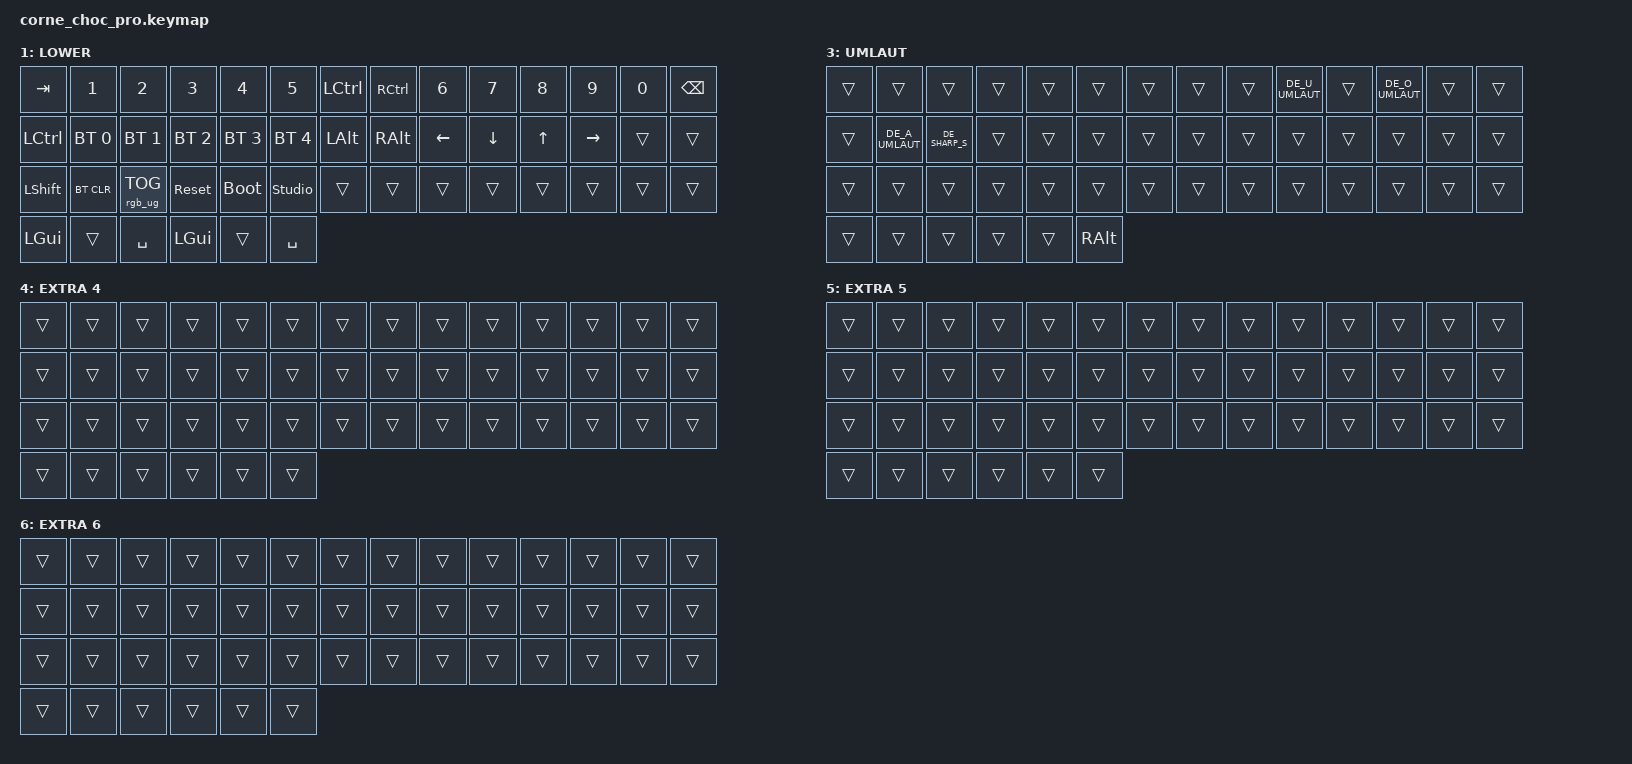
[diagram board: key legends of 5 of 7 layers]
/*
 * Copyright (c) 2020 The ZMK Contributors
 *
 * SPDX-License-Identifier: MIT
 */

#include <behaviors.dtsi>
#include <dt-bindings/zmk/keys.h>
#include <dt-bindings/zmk/bt.h>
#include <dt-bindings/zmk/rgb.h>

/ {
    chosen {
        zmk,physical-layout = &default_layout;
    };
};

/ {
    keymap {
        compatible = "zmk,keymap";

        default_layer {
            display-name = "QWERTY";
            // --------------------------------------------------------------------------------
            // | TAB | Q | W | E | R | T | MUTE | PP | Y | U | I | O | P | BSPC |
            // | CTRL | A | S | D | F | G | LALT | MO3 | H | J | K | L | ; | ' |
            // | SHFT | Z | X | C | V | B | | N | M | , | . | / | ESC |
            // | GUI | LWR | SPC | | ENT | RSE | MO3 |
            bindings = <
                &kp TAB &kp Q &kp W &kp E &kp R &kp T &kp C_MUTE &kp C_PP &kp Y &kp U &kp I &kp O &kp P &kp BSPC
                &kp LCTRL &kp A &kp S &kp D &kp F &kp G &kp LALT  &kp H &kp J &kp K &kp L &kp SEMI &kp SQT
                &kp LSHFT &kp Z &kp X &kp C &kp V &kp B &kp N &kp M &kp COMMA &kp DOT &kp FSLH &kp ESC
                &kp LGUI &mo 1 &kp SPACE &kp RET &mo 2 
            >;
            sensor-bindings = <&inc_dec_kp C_VOL_DN C_VOL_UP &inc_dec_kp PG_UP PG_DN &inc_dec_kp C_PREV C_NEXT &inc_dec_kp C_BRI_DN C_BRI_UP>;
        };

        extra_layer_1 {
            display-name = "LOWER";
            bindings = <
                &kp TAB &kp N1 &kp N2 &kp N3 &kp N4 &kp N5 &kp LCTRL &kp RCTRL &kp N6 &kp N7 &kp N8 &kp N9 &kp N0 &kp BSPC
                &kp LCTRL &bt BT_SEL 0 &bt BT_SEL 1 &bt BT_SEL 2 &bt BT_SEL 3 &bt BT_SEL 4 &kp LALT &kp RALT &kp LEFT &kp DOWN &kp UP &kp RIGHT &trans &trans
                &kp LSHFT &bt BT_CLR &rgb_ug RGB_TOG &sys_reset &bootloader &studio_unlock &trans &trans &trans &trans &trans &trans &trans &trans
                &kp LGUI &trans &kp SPACE &kp LGUI &trans &kp SPACE
            >;
        };

        extra_layer_2 {
            display-name = "RAISE";
            bindings = <
                &kp TAB &kp EXCL &kp AT &kp HASH &kp DLLR &kp PRCNT &kp LCTRL &kp RCTRL &kp CARET &kp AMPS &kp ASTRK &kp LPAR &kp RPAR &kp BSPC
                &kp LCTRL &trans &trans &trans &trans &trans &kp LALT &kp RALT &kp MINUS &kp EQUAL &kp LBKT &kp RBKT &kp BSLH &kp GRAVE
                &kp LSHFT &trans &trans &trans &trans &trans &kp UNDER &kp PLUS &kp LBRC &kp RBRC &kp PIPE &kp TILDE &kp LGUI &trans
                &kp SPACE &kp RET &trans &kp RALT
            >;
        };

        extra_layer_3 {
            display-name = "UMLAUT";
            // Umlaut layer: Hold MO3 (was RALT/AltGr) to activate
            // A->Ä, O->Ö, U->Ü, S->ß, E->€, Z->å (optional)
            // Other keys pass through as transparent
            bindings = <
                &trans &trans &trans &trans &trans &trans &trans &trans &trans &kp DE_U_UMLAUT &trans &kp DE_O_UMLAUT &trans &trans
                &trans &kp DE_A_UMLAUT &kp DE_SHARP_S &trans &trans &trans &trans &trans &trans &trans &trans &trans &trans &trans
                &trans &trans &trans &trans &trans &trans &trans &trans &trans &trans &trans &trans &trans &trans
                &trans &trans &trans &trans &trans &kp RALT
            >;
        };

        extra_layer_4 {
            display-name = "EXTRA 4";
            bindings = <
                &trans &trans &trans &trans &trans &trans &trans &trans &trans &trans &trans &trans &trans &trans
                &trans &trans &trans &trans &trans &trans &trans &trans &trans &trans &trans &trans &trans &trans
                &trans &trans &trans &trans &trans &trans &trans &trans &trans &trans &trans &trans &trans &trans
                &trans &trans &trans &trans &trans &trans
            >;
        };

        extra_layer_5 {
            display-name = "EXTRA 5";
            bindings = <
                &trans &trans &trans &trans &trans &trans &trans &trans &trans &trans &trans &trans &trans &trans
                &trans &trans &trans &trans &trans &trans &trans &trans &trans &trans &trans &trans &trans &trans
                &trans &trans &trans &trans &trans &trans &trans &trans &trans &trans &trans &trans &trans &trans
                &trans &trans &trans &trans &trans &trans
            >;
        };

        extra_layer_6 {
            display-name = "EXTRA 6";
            bindings = <
                &trans &trans &trans &trans &trans &trans &trans &trans &trans &trans &trans &trans &trans &trans
                &trans &trans &trans &trans &trans &trans &trans &trans &trans &trans &trans &trans &trans &trans
                &trans &trans &trans &trans &trans &trans &trans &trans &trans &trans &trans &trans &trans &trans
                &trans &trans &trans &trans &trans &trans
            >;
        };
    };
};
